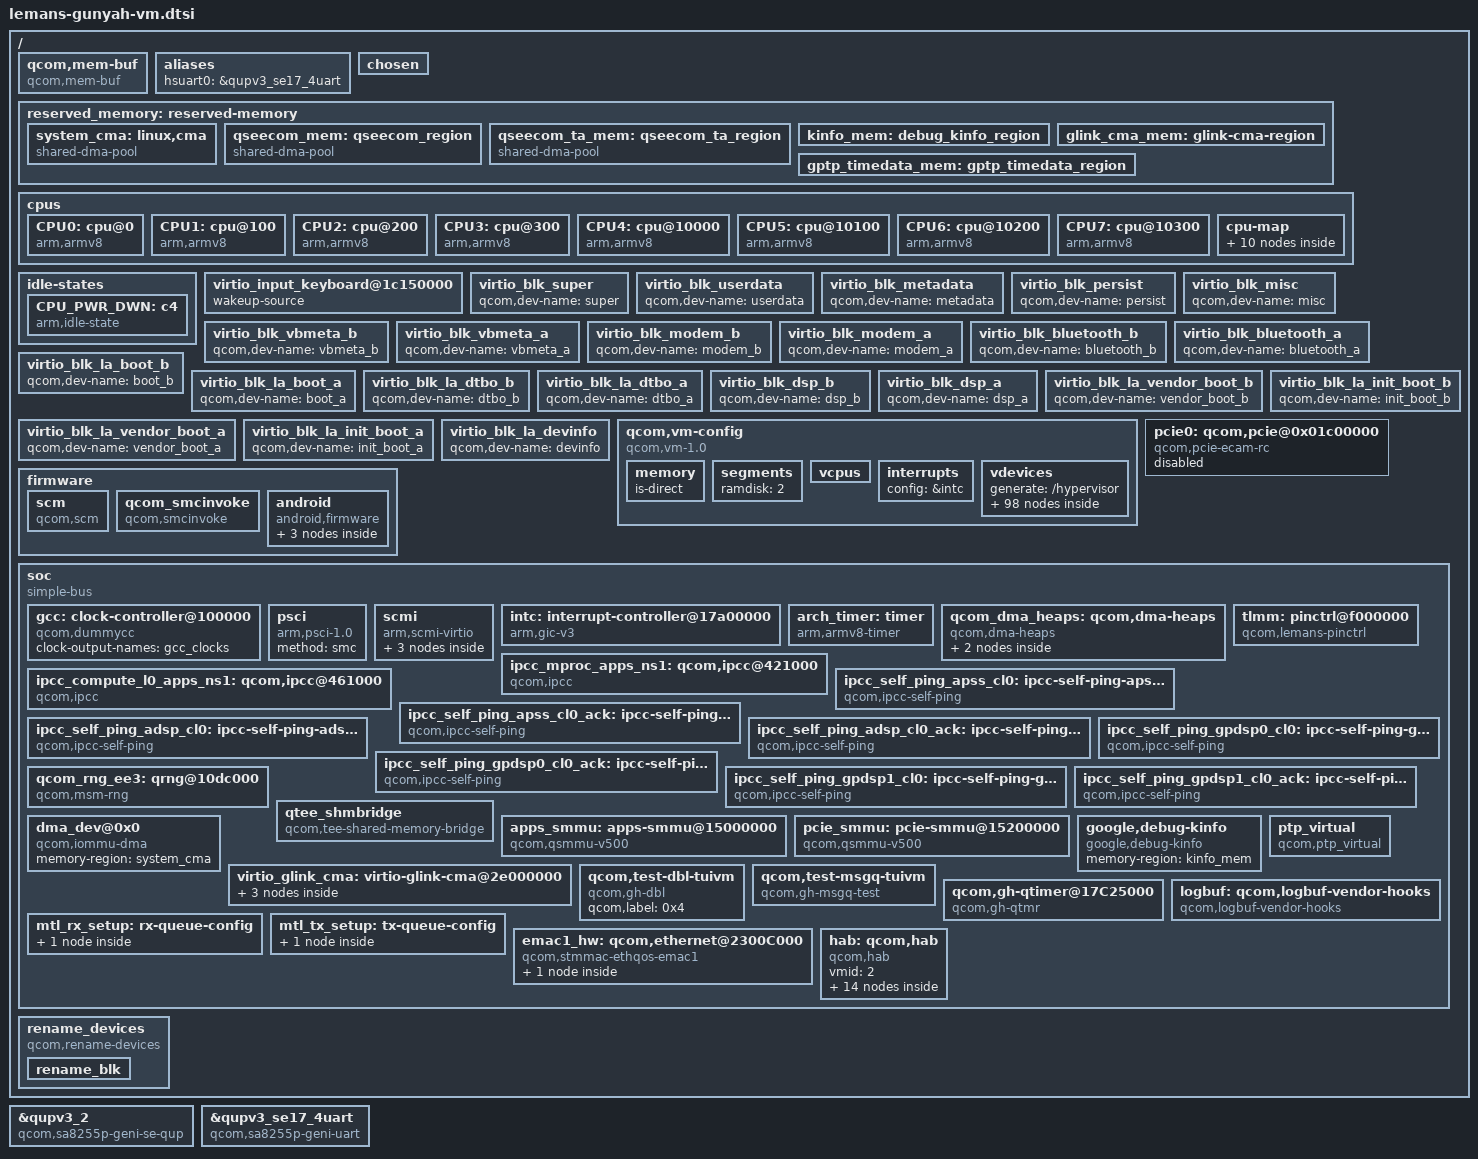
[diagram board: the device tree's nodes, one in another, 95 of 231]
#include <dt-bindings/interrupt-controller/arm-gic.h>
#include <dt-bindings/clock/qcom,gcc-lemans.h>
#include <dt-bindings/arm/msm/qcom_dma_heap_dt_constants.h>
#include <dt-bindings/mailbox/qcom-ipcc.h>
#include <dt-bindings/soc/qcom,ipcc.h>
/ {
	#address-cells = <0x2>;
	#size-cells = <0x2>;
	qcom,msm-id = <532 0x10000>, <533 0x10000>, <534 0x10000>, <532 0x20000>, <533 0x20000>, <534 0x20000>;
	interrupt-parent = <&intc>;

	qcom,mem-buf {
		compatible = "qcom,mem-buf";
		qcom,mem-buf-capabilities = "consumer";
		qcom,vmid = <52>;
	};

	aliases {
		hsuart0 = &qupv3_se17_4uart;
	};

	chosen {
		bootargs = "nokaslr log_buf_len=1M ufshcd-core.use_mcq_mode=n";
	};

	reserved_memory: reserved-memory {
		#address-cells = <2>;
		#size-cells = <2>;
		ranges;

		system_cma: linux,cma {
			compatible = "shared-dma-pool";
			alloc-ranges = <0x0 0x0 0x0 0xffffffff>;
			reusable;
			alignment = <0x0 0x400000>;
			size = <0x0 0x2000000>;
			linux,cma-default;
		};

		qseecom_mem: qseecom_region {
			compatible = "shared-dma-pool";
			alloc-ranges = <0x0 0x00000000 0x0 0xffffffff>;
			reusable;
			alignment = <0x0 0x400000>;
			size = <0x0 0x1400000>;
		};

		qseecom_ta_mem: qseecom_ta_region {
			compatible = "shared-dma-pool";
			alloc-ranges = <0x0 0x00000000 0x0 0xffffffff>;
			reusable;
			alignment = <0x0 0x400000>;
			size = <0x0 0x1000000>;
		};

		kinfo_mem: debug_kinfo_region {
			alloc-ranges = <0x0 0x0 0xffffffff 0xffffffff>;
			size = <0x0 0x1000>;
			no-map;
		};

		glink_cma_mem: glink-cma-region {
			no-map;
			qcom,label = <0x60>;
		};

		gptp_timedata_mem: gptp_timedata_region {
			no-map;
			qcom,label = <0x61>;
		};
	};

	cpus {
		#address-cells = <0x2>;
		#size-cells = <0x0>;

		CPU0: cpu@0 {
			compatible = "arm,armv8";
			reg = <0x0 0x0>;
			device_type = "cpu";
			enable-method = "psci";
			cpu-idle-states = <&CPU_PWR_DWN>;
		};

		CPU1: cpu@100 {
			compatible = "arm,armv8";
			reg = <0x0 0x100>;
			device_type = "cpu";
			enable-method = "psci";
			cpu-idle-states = <&CPU_PWR_DWN>;
		};

		CPU2: cpu@200 {
			compatible = "arm,armv8";
			reg = <0x0 0x200>;
			device_type = "cpu";
			enable-method = "psci";
			cpu-idle-states = <&CPU_PWR_DWN>;
		};

		CPU3: cpu@300 {
			compatible = "arm,armv8";
			reg = <0x0 0x300>;
			device_type = "cpu";
			enable-method = "psci";
			cpu-idle-states = <&CPU_PWR_DWN>;
		};

		CPU4: cpu@10000 {
			compatible = "arm,armv8";
			reg = <0x0 0x10000>;
			device_type = "cpu";
			enable-method = "psci";
			cpu-idle-states = <&CPU_PWR_DWN>;
		};

		CPU5: cpu@10100 {
			compatible = "arm,armv8";
			reg = <0x0 0x10100>;
			device_type = "cpu";
			enable-method = "psci";
			cpu-idle-states = <&CPU_PWR_DWN>;
		};

		CPU6: cpu@10200 {
			compatible = "arm,armv8";
			reg = <0x0 0x10200>;
			device_type = "cpu";
			enable-method = "psci";
			cpu-idle-states = <&CPU_PWR_DWN>;
		};

		CPU7: cpu@10300 {
			compatible = "arm,armv8";
			reg = <0x0 0x10300>;
			device_type = "cpu";
			enable-method = "psci";
			cpu-idle-states = <&CPU_PWR_DWN>;
		};

		cpu-map {
			cluster0 {
				core0 {
					cpu = <&CPU0>;
				};

				core1 {
					cpu = <&CPU1>;
				};

				core2 {
					cpu = <&CPU2>;
				};

				core3 {
					cpu = <&CPU3>;
				};
			};

			cluster1 {
				core0 {
					cpu = <&CPU4>;
				};

				core1 {
					cpu = <&CPU5>;
				};

				core2 {
					cpu = <&CPU6>;
				};

				core3 {
					cpu = <&CPU7>;
				};
			};
		};
	};

	idle-states {
		CPU_PWR_DWN: c4 { /* C4 */
			compatible = "arm,idle-state";
			idle-state-name = "rail-pc";
			entry-latency-us = <702>;
			exit-latency-us = <1061>;
			min-residency-us = <4488>;
			arm,psci-suspend-param = <0x40000004>;
			local-timer-stop;
		};
	};

	virtio_input_keyboard@1c150000 {
		wakeup-source;
	};

	virtio_blk_super {
		qcom,dev-name = "super";
	};

	virtio_blk_userdata {
		qcom,dev-name = "userdata";
	};

	virtio_blk_metadata {
		qcom,dev-name = "metadata";
	};

	virtio_blk_persist {
		qcom,dev-name = "persist";
	};

	virtio_blk_misc {
		qcom,dev-name = "misc";
	};

	virtio_blk_vbmeta_b {
		qcom,dev-name = "vbmeta_b";
	};

	virtio_blk_vbmeta_a {
		qcom,dev-name = "vbmeta_a";
	};

	virtio_blk_modem_b {
		qcom,dev-name = "modem_b";
	};

	virtio_blk_modem_a {
		qcom,dev-name = "modem_a";
	};

	virtio_blk_bluetooth_b {
		qcom,dev-name = "bluetooth_b";
	};

	virtio_blk_bluetooth_a {
		qcom,dev-name = "bluetooth_a";
	};

	virtio_blk_la_boot_b {
		qcom,dev-name = "boot_b";
	};

	virtio_blk_la_boot_a {
		qcom,dev-name = "boot_a";
	};

	virtio_blk_la_dtbo_b {
		qcom,dev-name = "dtbo_b";
	};

	virtio_blk_la_dtbo_a {
		qcom,dev-name = "dtbo_a";
	};

	virtio_blk_dsp_b {
		qcom,dev-name = "dsp_b";
	};

	virtio_blk_dsp_a {
		qcom,dev-name = "dsp_a";
	};

	virtio_blk_la_vendor_boot_b {
		qcom,dev-name = "vendor_boot_b";
	};

	virtio_blk_la_vendor_boot_a {
		qcom,dev-name = "vendor_boot_a";
	};

	virtio_blk_la_init_boot_b {
		qcom,dev-name = "init_boot_b";
	};

	virtio_blk_la_init_boot_a {
		qcom,dev-name = "init_boot_a";
	};

	virtio_blk_la_devinfo {
		qcom,dev-name = "devinfo";
	};

	qcom,vm-config {
		compatible = "qcom,vm-1.0";
		vm-type = "aarch64-guest";
		boot-config = "fdt,unified";
		os-type = "linux";
		kernel-entry-segment = "kernel";
		kernel-entry-offset = <0x0 0x0>;
		vendor = "QTI";
		image-name = "qcom,autoghgvm";
		qcom,pasid = <0x0 0x2c>;
		qcom,qtee-config-info = "p=3,16,57,77,78,7A,7C,8F,97,159,199,47E,7F1,10C;";
		qcom,secdomain-ids = <52 9 10>;
		qcom,primary-vm-index = <0>;
		vm-attrs = "guest-ram-dump", "vpm-virq";

		/* Pass through regions */
		iomemory-ranges = <
				/* TLMM region */
				0x0 0xF000000 0x0 0xF000000 0x0 0x1000000 0x0
				/* QUPv3 Tile 2 read-only region */
				0x0 0x8C0000 0x0 0x8C0000 0x0 0x1000 0x1
				0x0 0x8C1000 0x0 0x8C1000 0x0 0x1000 0x1
				/* QUPv3 SE17 region */
				0x0 0x88C000 0x0 0x88C000 0x0 0x1000 0x0
				0x0 0x88D000 0x0 0x88D000 0x0 0x1000 0x0
				0x0 0x88E000 0x0 0x88E000 0x0 0x1000 0x0
				/* QRNG region */
				0x0 0x10dc000 0x0 0x10dc000 0x0 0x1000 0x0
				/* MPROC NS1 IPCC region */
				0x0 0x421000 0x0 0x421000 0x0 0x1000 0x0
				/* Compute L0 IPCC region */
				0x0 0x461000 0x0 0x461000 0x0 0x1000 0x0
				0x0 0x1fd8000 0x0 0x1fd8000 0x0 0x1000 0x1
				0x0 0x1fd9000 0x0 0x1fd9000 0x0 0x1000 0x3
				0x0 0x1fdd000 0x0 0x1fdd000 0x0 0x1000 0x3
				0x0 0x1fdb000 0x0 0x1fdb000 0x0 0x1000 0x0
				0x0 0x1fdf000 0x0 0x1fdf000 0x0 0x1000 0x0
				/* Board serial number region */
				0x0 0x786000 0x0 0x786000 0x0 0x1000 0x1
				/* PTP region */
				0x0 0x23047000 0x0 0x23047000 0x0 0x1000 0x0
				/* Qtimer region */
				0x0 0x17c23000 0x0 0x17c23000 0x0 0x1000 0x0
				/* MPM timer read only*/
				0x0 0xc221000 0x0 0xc221000 0x0 0x1000 0x1
				/* PCIe0 region */
				0x4 0x0 0x4 0x0 0x0 0x10000000 0x0
				0x0 0x40000000 0x0 0x40000000 0x0 0x100000 0x0
				0x0 0x40100000 0x0 0x40100000 0x0 0x1ff00000 0x0
				0x4 0x10100000 0x4 0x10100000 0x0 0x100000 0x0
				/* EMAC1 CH4 region */
				0x0 0x2300C000 0x0 0x2300C000 0x0 0x1000 0x0
				>;

		/* Pass through IRQs */
		gic-irq-ranges = <
			/* QUPv3 SE17 GIC IRQ */
			617 617
			/* MPROC NS1 IPCC GIC IRQ */
			591 591
			/* Compute L0 IPCC GIC IRQ */
			588 588
			270 270
			271 271
			/* PCIe0 IRQs */
			339 339
			340 340
			341 341
			344 344
			345 345
			346 346
			406 406
			407 407
			/* EMAC1 CH4 GIC IRQ */
			808 808
			860 860
			>;

		memory {
			#address-cells = <0x2>;
			#size-cells = <0x0>;

			/* The IPA of the Guest regions is placed as IPA=PA */
			is-direct;
		};

		segments {
			ramdisk = <2>;
		};

		vcpus {
			config = "/cpus";
			affinity = "pinned";
			affinity-map = <0x7 0x6 0x5 0x4 0x3 0x2 0x1 0x0>;
			sched-priority = <0>;       /* relative to PVM */
			sched-timeslice = <5000>;   /* in ms */
		};

		interrupts {
			config = &intc;
		};

		vdevices {
			generate = "/hypervisor";
			minidump {
				vdevice-type = "minidump";
				push-compatible = "qcom,minidump_rm";
				minidump_allowed;
			};

			rm-rpc {
				vdevice-type = "rm-rpc";
				generate = "/hypervisor/qcom,resource-mgr";
				console-dev;
				message-size = <0x000000f0>;
				queue-depth = <0x00000008>;
				qcom,label = <0x1>;
			};

			virtio-mmio@0 {
				vdevice-type = "virtio-mmio";
				generate = "/virtio-mmio";
				peer-default;
				vqs-num = <0x1>;
				push-compatible = "virtio,mmio";
				sync-reset;
				dma-coherent;
				dma_base = <0x0 0x0>;
				memory {
					qcom,label = <0x20>;
					#address-cells = <0x2>;
					allocate-base;
				};
			};

			virtio-mmio@1 {
				vdevice-type = "virtio-mmio";
				patch = "/virtio_blk_la_devinfo";
				peer-default;
				vqs-num = <0x1>;
				push-compatible = "virtio,mmio";
				sync-reset;
				dma-coherent;
				dma_base = <0x0 0x4000>;
				memory {
					qcom,label = <0x21>;
					#address-cells = <0x2>;
					allocate-base;
				};
			};

			virtio-mmio@2 {
				vdevice-type = "virtio-mmio";
				patch = "/virtio_blk_la_init_boot_a";
				peer-default;
				vqs-num = <0x1>;
				push-compatible = "virtio,mmio";
				sync-reset;
				dma-coherent;
				dma_base = <0x0 0x8000>;
				memory {
					qcom,label = <0x22>;
					#address-cells = <0x2>;
					allocate-base;
				};
			};

			virtio-mmio@3 {
				vdevice-type = "virtio-mmio";
				patch = "/virtio_blk_la_init_boot_b";
				peer-default;
				vqs-num = <0x1>;
				push-compatible = "virtio,mmio";
				sync-reset;
				dma-coherent;
				dma_base = <0x0 0xC000>;
				memory {
					qcom,label = <0x23>;
					#address-cells = <0x2>;
					allocate-base;
				};
			};

			virtio-mmio@4 {
				vdevice-type = "virtio-mmio";
				patch = "/virtio_blk_la_vendor_boot_a";
				peer-default;
				vqs-num = <0x1>;
				push-compatible = "virtio,mmio";
				sync-reset;
				dma-coherent;
				dma_base = <0x0 0x10000>;
				memory {
					qcom,label = <0x24>;
					#address-cells = <0x2>;
					allocate-base;
				};
			};

			virtio-mmio@5 {
				vdevice-type = "virtio-mmio";
				patch = "/virtio_blk_la_vendor_boot_b";
				peer-default;
				vqs-num = <0x1>;
				push-compatible = "virtio,mmio";
				sync-reset;
				dma-coherent;
				dma_base = <0x0 0x14000>;
				memory {
					qcom,label = <0x25>;
					#address-cells = <0x2>;
					allocate-base;
				};
			};

			virtio-mmio@6 {
				vdevice-type = "virtio-mmio";
				patch = "/virtio_blk_dsp_a";
				peer-default;
				vqs-num = <0x1>;
				push-compatible = "virtio,mmio";
				sync-reset;
				dma-coherent;
				dma_base = <0x0 0x18000>;
				memory {
					qcom,label = <0x26>;
					#address-cells = <0x2>;
					allocate-base;
				};
			};

			virtio-mmio@7 {
				vdevice-type = "virtio-mmio";
				patch = "/virtio_blk_dsp_b";
				peer-default;
				vqs-num = <0x1>;
				push-compatible = "virtio,mmio";
				sync-reset;
				dma-coherent;
				dma_base = <0x0 0x1C000>;
				memory {
					qcom,label = <0x27>;
					#address-cells = <0x2>;
					allocate-base;
				};
			};

			virtio-mmio@8 {
				vdevice-type = "virtio-mmio";
				patch = "/virtio_blk_la_dtbo_a";
				peer-default;
				vqs-num = <0x1>;
				push-compatible = "virtio,mmio";
				sync-reset;
				dma-coherent;
				dma_base = <0x0 0x20000>;
				memory {
					qcom,label = <0x28>;
					#address-cells = <0x2>;
					allocate-base;
				};
			};

			virtio-mmio@9 {
				vdevice-type = "virtio-mmio";
				patch = "/virtio_blk_la_dtbo_b";
				peer-default;
				vqs-num = <0x1>;
				push-compatible = "virtio,mmio";
				sync-reset;
				dma-coherent;
				dma_base = <0x0 0x24000>;
				memory {
					qcom,label = <0x29>;
					#address-cells = <0x2>;
					allocate-base;
				};
			};

			virtio-mmio@10 {
				vdevice-type = "virtio-mmio";
				patch = "/virtio_blk_la_boot_a";
				peer-default;
				vqs-num = <0x1>;
				push-compatible = "virtio,mmio";
				sync-reset;
				dma-coherent;
				dma_base = <0x0 0x28000>;
				memory {
					qcom,label = <0x2A>;
					#address-cells = <0x2>;
					allocate-base;
				};
			};

			virtio-mmio@11 {
				vdevice-type = "virtio-mmio";
				patch = "/virtio_blk_la_boot_b";
				peer-default;
				vqs-num = <0x1>;
				push-compatible = "virtio,mmio";
				sync-reset;
				dma-coherent;
				dma_base = <0x0 0x2C000>;
				memory {
					qcom,label = <0x2B>;
					#address-cells = <0x2>;
					allocate-base;
				};
			};

			virtio-mmio@12 {
				vdevice-type = "virtio-mmio";
				patch = "/virtio_blk_bluetooth_a";
				peer-default;
				vqs-num = <0x1>;
				push-compatible = "virtio,mmio";
				sync-reset;
				dma-coherent;
				dma_base = <0x0 0x30000>;
				memory {
					qcom,label = <0x2C>;
					#address-cells = <0x2>;
					allocate-base;
				};
			};

			virtio-mmio@13 {
				vdevice-type = "virtio-mmio";
				patch = "/virtio_blk_bluetooth_b";
				peer-default;
				vqs-num = <0x1>;
				push-compatible = "virtio,mmio";
				sync-reset;
				dma-coherent;
				dma_base = <0x0 0x34000>;
				memory {
					qcom,label = <0x2D>;
					#address-cells = <0x2>;
					allocate-base;
				};
			};

			virtio-mmio@14 {
				vdevice-type = "virtio-mmio";
				patch = "/virtio_blk_modem_a";
				peer-default;
				vqs-num = <0x1>;
				push-compatible = "virtio,mmio";
				sync-reset;
				dma-coherent;
				dma_base = <0x0 0x38000>;
				memory {
					qcom,label = <0x2E>;
					#address-cells = <0x2>;
					allocate-base;
				};
			};

			virtio-mmio@15 {
				vdevice-type = "virtio-mmio";
				patch = "/virtio_blk_modem_b";
				peer-default;
				vqs-num = <0x1>;
				push-compatible = "virtio,mmio";
				sync-reset;
				dma-coherent;
				dma_base = <0x0 0x3C000>;
				memory {
					qcom,label = <0x2F>;
					#address-cells = <0x2>;
					allocate-base;
				};
			};

			virtio-mmio@16 {
				vdevice-type = "virtio-mmio";
				patch = "/virtio_blk_vbmeta_a";
				peer-default;
				vqs-num = <0x1>;
				push-compatible = "virtio,mmio";
				sync-reset;
				dma-coherent;
				dma_base = <0x0 0x40000>;
				memory {
					qcom,label = <0x30>;
					#address-cells = <0x2>;
					allocate-base;
				};
			};

			virtio-mmio@17 {
				vdevice-type = "virtio-mmio";
				patch = "/virtio_blk_vbmeta_b";
				peer-default;
				vqs-num = <0x1>;
				push-compatible = "virtio,mmio";
				sync-reset;
				dma-coherent;
				dma_base = <0x0 0x44000>;
				memory {
					qcom,label = <0x31>;
					#address-cells = <0x2>;
					allocate-base;
				};
			};

			virtio-mmio@18 {
				vdevice-type = "virtio-mmio";
				patch = "/virtio_blk_misc";
				peer-default;
				vqs-num = <0x1>;
				push-compatible = "virtio,mmio";
				sync-reset;
				dma-coherent;
				dma_base = <0x0 0x48000>;
				memory {
					qcom,label = <0x32>;
					#address-cells = <0x2>;
					allocate-base;
				};
			};

			virtio-mmio@19 {
				vdevice-type = "virtio-mmio";
				patch = "/virtio_blk_persist";
				peer-default;
				vqs-num = <0x1>;
				push-compatible = "virtio,mmio";
				sync-reset;
				dma-coherent;
				dma_base = <0x0 0x4C000>;
				memory {
					qcom,label = <0x33>;
					#address-cells = <0x2>;
					allocate-base;
				};
			};

			virtio-mmio@20 {
				vdevice-type = "virtio-mmio";
				patch = "/virtio_blk_metadata";
				peer-default;
				vqs-num = <0x1>;
				push-compatible = "virtio,mmio";
				sync-reset;
				dma-coherent;
				dma_base = <0x0 0x50000>;
				memory {
					qcom,label = <0x34>;
					#address-cells = <0x2>;
					allocate-base;
				};
			};

			virtio-mmio@21 {
				vdevice-type = "virtio-mmio";
				patch = "/virtio_blk_userdata";
				peer-default;
				vqs-num = <0x1>;
				push-compatible = "virtio,mmio";
				sync-reset;
				dma-coherent;
				dma_base = <0x0 0x54000>;
				memory {
					qcom,label = <0x35>;
					#address-cells = <0x2>;
					allocate-base;
				};
			};

			virtio-mmio@22 {
				vdevice-type = "virtio-mmio";
				patch = "/virtio_blk_super";
				peer-default;
				vqs-num = <0x1>;
				push-compatible = "virtio,mmio";
				sync-reset;
				dma-coherent;
				dma_base = <0x0 0x58000>;
				memory {
					qcom,label = <0x36>;
					#address-cells = <0x2>;
					allocate-base;
				};
			};

			virtio-mmio@23 {
				vdevice-type = "virtio-mmio";
				generate = "/virtio-mmio";
				peer-default;
				vqs-num = <0x2>;
				push-compatible = "virtio,mmio";
				sync-reset;
				dma-coherent;
				dma_base = <0x0 0x5C000>;
				memory {
					qcom,label = <0x37>;
					#address-cells = <0x2>;
					allocate-base;
				};
			};

			virtio-mmio@24 {
				vdevice-type = "virtio-mmio";
				generate = "/virtio-mmio";
				peer-default;
				vqs-num = <0x2>;
				push-compatible = "virtio,mmio";
				sync-reset;
				dma-coherent;
				dma_base = <0x0 0x64000>;
				memory {
					qcom,label = <0x38>;
					#address-cells = <0x2>;
					allocate-base;
				};
			};

			virtio-mmio@25 {
				vdevice-type = "virtio-mmio";
				generate = "/virtio-mmio";
				peer-default;
				vqs-num = <0x2>;
				push-compatible = "virtio,mmio";
				sync-reset;
				dma-coherent;
				dma_base = <0x0 0x6C000>;
				memory {
					qcom,label = <0x39>;
					#address-cells = <0x2>;
					allocate-base;
				};
			};

			virtio-mmio@26 {
				vdevice-type = "virtio-mmio";
				generate = "/virtio-mmio";
				peer-default;
				vqs-num = <0x2>;
				push-compatible = "virtio,mmio";
				sync-reset;
				dma-coherent;
				dma_base = <0x0 0x7C000>;
				memory {
					qcom,label = <0x3A>;
					#address-cells = <0x2>;
					allocate-base;
				};
			};

			virtio-mmio@27 {
				vdevice-type = "virtio-mmio";
				generate = "/virtio-mmio";
				peer-default;
				vqs-num = <0x8>;
				push-compatible = "virtio,mmio";
				sync-reset;
				dma-coherent;
				dma_base = <0x0 0x8C000>;
				memory {
					qcom,label = <0x3B>;
					#address-cells = <0x2>;
					allocate-base;
				};
			};

			virtio-mmio@28 {
				vdevice-type = "virtio-mmio";
				generate = "/virtio-mmio";
				peer-default;
				vqs-num = <0xA>;
				push-compatible = "virtio,mmio";
				sync-reset;
				dma-coherent;
				dma_base = <0x0 0xCC000>;
				memory {
					qcom,label = <0x3C>;
					#address-cells = <0x2>;
					allocate-base;
				};
			};

			virtio-mmio@29 {
				vdevice-type = "virtio-mmio";
				generate = "/virtio-mmio";
				peer-default;
				vqs-num = <0x6>;
				push-compatible = "virtio,mmio";
				sync-reset;
				dma-coherent;
				dma_base = <0x0 0x11C000>;
				memory {
					qcom,label = <0x3D>;
					#address-cells = <0x2>;
					allocate-base;
				};
			};

			virtio-mmio@30 {
				vdevice-type = "virtio-mmio";
				generate = "/virtio-mmio";
				peer-default;
				vqs-num = <0x6>;
				push-compatible = "virtio,mmio";
				sync-reset;
				dma-coherent;
				dma_base = <0x0 0x14C000>;
				memory {
					qcom,label = <0x3E>;
					#address-cells = <0x2>;
					allocate-base;
				};
			};

			virtio-mmio@31 {
				vdevice-type = "virtio-mmio";
				generate = "/virtio-mmio";
				virtio,device-type = <18>;
				peer-default;
				vqs-num = <0x2>;
				push-compatible = "virtio,mmio";
				sync-reset;
				dma-coherent;
				dma_base = <0x0 0x17C000>;
				memory {
					qcom,label = <0x3F>;
					#address-cells = <0x2>;
					allocate-base;
				};
			};

			virtio-mmio@32 {
				vdevice-type = "virtio-mmio";
				patch = "/virtio_input_keyboard@1c150000";
				virtio,device-type = <18>;
				peer-default;
				vqs-num = <0x2>;
				push-compatible = "virtio,mmio";
				sync-reset;
				dma-coherent;
				dma_base = <0x0 0x180000>;
				memory {
					qcom,label = <0x40>;
					#address-cells = <0x2>;
					allocate-base;
				};
			};

			virtio-mmio@33 {
				vdevice-type = "virtio-mmio";
				generate = "/virtio-mmio";
				peer-default;
				vqs-num = <0x2>;
				push-compatible = "virtio,mmio";
				sync-reset;
				dma-coherent;
				dma_base = <0x0 0x184000>;
				memory {
					qcom,label = <0x41>;
					#address-cells = <0x2>;
					allocate-base;
				};
			};

			virtio-mmio@34 {
				vdevice-type = "virtio-mmio";
				generate = "/virtio-mmio";
				peer-default;
				vqs-num = <0x2>;
				push-compatible = "virtio,mmio";
				sync-reset;
				dma-coherent;
				dma_base = <0x0 0x18C000>;
				memory {
					qcom,label = <0x42>;
					#address-cells = <0x2>;
					allocate-base;
				};
			};

			virtio-mmio@35 {
				vdevice-type = "virtio-mmio";
				generate = "/virtio-mmio";
				peer-default;
				vqs-num = <0x3>;
				push-compatible = "virtio,mmio";
				sync-reset;
				dma-coherent;
				dma_base = <0x0 0x194000>;
				memory {
					qcom,label = <0x43>;
					#address-cells = <0x2>;
					allocate-base;
				};
			};

			virtio-mmio@36 {
				vdevice-type = "virtio-mmio";
				patch = "/soc/virtio-glink-cma@2e000000";
				peer-default;
				vqs-num = <0x1>;
				push-compatible = "virtio,mmio";
				sync-reset;
				dma-coherent;
				dma_base = <0x0 0x1A0000>;
				memory {
					qcom,label = <0x44>;
					#address-cells = <0x2>;
					allocate-base;
				};
			};

			virtio-mmio@37 {
				vdevice-type = "virtio-mmio";
				generate = "/virtio-mmio";
				peer-default;
				vqs-num = <0x2>;
				push-compatible = "virtio,mmio";
				sync-reset;
				dma-coherent;
				dma_base = <0x0 0x1A2000>;
				memory {
					qcom,label = <0x45>;
					#address-cells = <0x2>;
					allocate-base;
				};
			};

			virtio-mmio@38 {
				vdevice-type = "virtio-mmio";
				generate = "/virtio-mmio";
				peer-default;
				vqs-num = <0x1>;
				push-compatible = "virtio,mmio";
				sync-reset;
				dma-coherent;
				dma_base = <0x0 0x1A6000>;
				memory {
					qcom,label = <0x46>;
					#address-cells = <0x2>;
					allocate-base;
				};
			};

			virtio-mmio@39 {
				vdevice-type = "virtio-mmio";
				generate = "/virtio-mmio";
				peer-default;
				vqs-num = <0x1>;
				push-compatible = "virtio,mmio";
				sync-reset;
				dma-coherent;
				dma_base = <0x0 0x1A8000>;
				memory {
					qcom,label = <0x47>;
					#address-cells = <0x2>;
					allocate-base;
				};
			};

			virtio-mmio@40 {
				vdevice-type = "virtio-mmio";
				generate = "/virtio-mmio";
				peer-default;
				vqs-num = <0x2>;
				push-compatible = "virtio,mmio";
				sync-reset;
				dma-coherent;
				dma_base = <0x0 0x1AA000>;
				memory {
					qcom,label = <0x48>;
					#address-cells = <0x2>;
					allocate-base;
				};
			};

			virtio-mmio@41 {
				vdevice-type = "virtio-mmio";
				generate = "/virtio-mmio";
				peer-default;
				vqs-num = <0x2>;
				push-compatible = "virtio,mmio";
				sync-reset;
				dma-coherent;
				dma_base = <0x0 0x1BA000>;
				memory {
					qcom,label = <0x49>;
					#address-cells = <0x2>;
					allocate-base;
				};
			};

			virtio-mmio@42 {
				vdevice-type = "virtio-mmio";
				generate = "/virtio-mmio";
				peer-default;
				vqs-num = <0x6>;
				push-compatible = "virtio,mmio";
				sync-reset;
				dma-coherent;
				dma_base = <0x0 0x1CA000>;
				memory {
					qcom,label = <0x4A>;
					#address-cells = <0x2>;
					allocate-base;
				};
			};

			virtio-mmio@43 {
				vdevice-type = "virtio-mmio";
				generate = "/virtio-mmio";
				peer-default;
				vqs-num = <0x2>;
				push-compatible = "virtio,mmio";
				sync-reset;
				dma-coherent;
				dma_base = <0x0 0x1FA000>;
				memory {
					qcom,label = <0x4B>;
					#address-cells = <0x2>;
					allocate-base;
				};
			};

			swiotlb-shm {
				vdevice-type = "shm";
				generate = "/swiotlb";
				push-compatible = "swiotlb";
				peer-default;
				dma_base = <0x0 0x1000000>;
				memory {
					qcom,label = <0x50>;
					#address-cells = <0x2>;
					allocate-base;
				};
			};

			vsmmu@15000000 {
				vdevice-type = "vsmmu-v2";
				smmu-handle = <0x15000000>;
				num-cbs = <0x4>;
				num-smrs = <0x4>;
				patch = "/soc/apps-smmu@15000000";
			};

			vsmmu@15200000 {
				vdevice-type = "vsmmu-v2";
				smmu-handle = <0x15200000>;
				num-cbs = <0x1>;
				num-smrs = <0x10>;
				patch = "/soc/pcie-smmu@15200000";
			};

			test-dbl-tuivm {
				vdevice-type = "doorbell";
				generate = "/hypervisor/test-dbl-tuivm";
				qcom,label = <0x4>;
				peer-default;
			};

			test-dbl-tuivm-source {
				vdevice-type = "doorbell-source";
				generate = "/hypervisor/test-dbl-tuivm-source";
				qcom,label = <0x4>;
				peer-default;
			};

			test-msgq-tuivm {
				vdevice-type = "message-queue-pair";
				generate = "/hypervisor/test-msgq-tuivm-pair";
				message-size = <0xf0>;
				queue-depth = <0x8>;
				qcom,label = <0x4>;
				peer-default;
			};

			vcpu-sched-test-msgq {
				vdevice-type = "message-queue-pair";
				generate = "/hypervisor/sched-test-msgq-pair";
				message-size = <0xf0>;
				queue-depth = <0x8>;
				qcom,label = <0x8>;
				peer-default;
			};
		};
	};

	firmware: firmware {
		scm {
			compatible = "qcom,scm";
		};

		qcom_smcinvoke {
			compatible = "qcom,smcinvoke";
		};

		android {
			compatible = "android,firmware";
			boot_devices = "70002000.virtio_blk_la_devinfo,70003000.virtio_blk_la_init_boot_a,70004000.virtio_blk_la_init_boot_b,70005000.virtio_blk_la_vendor_boot_a,70006000.virtio_blk_la_vendor_boot_b,70007000.virtio_blk_dsp_a,70008000.virtio_blk_dsp_b,70009000.virtio_blk_la_dtbo_a,7000a000.virtio_blk_la_dtbo_b,7000b000.virtio_blk_la_boot_a,7000c000.virtio_blk_la_boot_b,7000d000.virtio_blk_bluetooth_a,7000e000.virtio_blk_bluetooth_b,7000f000.virtio_blk_modem_a,70010000.virtio_blk_modem_b,70011000.virtio_blk_vbmeta_a,70012000.virtio_blk_vbmeta_b,70013000.virtio_blk_misc,70014000.virtio_blk_persist,70015000.virtio_blk_metadata,70016000.virtio_blk_userdata,70017000.virtio_blk_super";

			vbmeta {
				compatible = "android,vbmeta";
				parts = "vbmeta,system,vendor";
			};

			fstab {
				compatible = "android,fstab";
				vendor {
					compatible = "android,vendor";
					dev="/dev/block/platform/vdevs/1c0f0000.virtio_blk/vdc";
					type = "ext4";
					mnt_flags = "ro,barrier=1,discard";
					fsmgr_flags = "wait";
					status = "disabled";
				};
			};
		};
	};

	pcie0: qcom,pcie@0x01c00000 {
		compatible = "qcom,pcie-ecam-rc";
		reg = <0x4 0x00000000 0x0 0x10000000>;
		device_type = "pci";

		#address-cells = <3>;
		#size-cells = <2>;
		ranges = <0x01000000 0x0 0x40000000 0x0 0x40000000 0x0 0x100000>,
				<0x02000000 0x0 0x40100000 0x0 0x40100000 0x0 0x1ff00000>,
				<0x43000000 0x4 0x10100000 0x4 0x10100000 0x0 0x100000>;
		interrupt-parent = <&intc>;

		bus-range = <0x00 0xff>;
		dma-coherent;
		linux,pci-domain = <0>;

		power-domains = <&scmi_power 1>;
		power-domain-names = "power";

		interrupts = <GIC_SPI 307 IRQ_TYPE_LEVEL_HIGH>,
			<GIC_SPI 308 IRQ_TYPE_LEVEL_HIGH>,
			<GIC_SPI 309 IRQ_TYPE_LEVEL_HIGH>,
			<GIC_SPI 312 IRQ_TYPE_LEVEL_HIGH>,
			<GIC_SPI 313 IRQ_TYPE_LEVEL_HIGH>,
			<GIC_SPI 314 IRQ_TYPE_LEVEL_HIGH>,
			<GIC_SPI 374 IRQ_TYPE_LEVEL_HIGH>,
			<GIC_SPI 375 IRQ_TYPE_LEVEL_HIGH>;

		iommus = <&pcie_smmu 0x00 0x7f>;
		iommu-map = <0x0 &pcie_smmu 0x0000 0x1>,
			<0x100 &pcie_smmu 0x0001 0x1>;

		status = "disabled";
	};

	soc: soc { };
};

&soc {
	#address-cells = <1>;
	#size-cells = <1>;
	ranges = <0 0 0 0xffffffff>;
	compatible = "simple-bus";

	gcc: clock-controller@100000 {
		compatible = "qcom,dummycc";
		clock-output-names = "gcc_clocks";
		#clock-cells = <1>;
		#reset-cells = <1>;
	};

	psci {
		compatible = "arm,psci-1.0";
		method = "smc";
	};

	scmi {
		compatible = "arm,scmi-virtio";
		#address-cells = <1>;
		#size-cells = <0>;
		status = "ok";

		scmi_power: protocol@11 {
			reg = <0x11>;
			#power-domain-cells = <1>;
		};

		scmi_perf: protocol@13 {
			reg = <0x13>;
			#power-domain-cells = <1>;
		};

		scmi_reset: protocol@16 {
			reg = <0x16>;
			#reset-cells = <1>;
		};
	};

	intc: interrupt-controller@17a00000 {
		compatible = "arm,gic-v3";
		interrupt-controller;
		#interrupt-cells = <0x3>;
		#redistributor-regions = <1>;
		redistributor-stride = <0x0 0x20000>;
		reg = <0x17a00000 0x10000>,     /* GICD */
		      <0x17a60000 0x100000>;    /* GICR * 8 */
	};

	arch_timer: timer {
		compatible = "arm,armv8-timer";
		always-on;
		interrupts = <GIC_PPI 13 (GIC_CPU_MASK_SIMPLE(8) | IRQ_TYPE_LEVEL_LOW)>,
			     <GIC_PPI 14 (GIC_CPU_MASK_SIMPLE(8) | IRQ_TYPE_LEVEL_LOW)>,
			     <GIC_PPI 11 (GIC_CPU_MASK_SIMPLE(8) | IRQ_TYPE_LEVEL_LOW)>,
			     <GIC_PPI 12 (GIC_CPU_MASK_SIMPLE(8) | IRQ_TYPE_LEVEL_LOW)>;
		clock-frequency = <19200000>;
	};

	qcom_dma_heaps: qcom,dma-heaps {
		compatible = "qcom,dma-heaps";

		qcom,qseecom {
			qcom,dma-heap-name = "qcom,qseecom";
			qcom,dma-heap-type = <HEAP_TYPE_CMA>;
			memory-region = <&qseecom_mem>;
		};

		qcom,qseecom_ta {
			qcom,dma-heap-name = "qcom,qseecom-ta";
			qcom,dma-heap-type = <HEAP_TYPE_CMA>;
			memory-region = <&qseecom_ta_mem>;
		};
	};

	tlmm: pinctrl@f000000 {
		compatible = "qcom,lemans-pinctrl";
		reg = <0xf000000 0x1000000>;
		interrupts = <GIC_SPI 208 IRQ_TYPE_LEVEL_HIGH>;
		gpio-controller;
		#gpio-cells = <2>;
		interrupt-controller;
		#interrupt-cells = <2>;
	};

	ipcc_mproc_apps_ns1: qcom,ipcc@421000 {
		compatible = "qcom,ipcc";
		reg = <0x421000 0x1000>;
		interrupts = <GIC_SPI 559 IRQ_TYPE_LEVEL_HIGH>;
		interrupt-controller;
		#interrupt-cells = <3>;
		#mbox-cells = <2>;
		status = "ok";
	};

	ipcc_compute_l0_apps_ns1: qcom,ipcc@461000 {
		compatible = "qcom,ipcc";
		reg = <0x461000 0x1000>;
		interrupts = <GIC_SPI 556 IRQ_TYPE_LEVEL_HIGH>;
		interrupt-controller;
		#interrupt-cells = <3>;
		#mbox-cells = <2>;
		status = "ok";
	};

	ipcc_self_ping_apss_cl0: ipcc-self-ping-apss_cl0 {
		compatible = "qcom,ipcc-self-ping";
		mboxes = <&ipcc_compute_l0_apps_ns1 IPCC_CLIENT_APSS
				IPCC_COMPUTE_L0_SIGNAL_MSG>;
		interrupt-parent = <&ipcc_compute_l0_apps_ns1>;
		interrupts = <IPCC_CLIENT_APSS
				IPCC_COMPUTE_L0_SIGNAL_MSG
				IRQ_TYPE_EDGE_RISING>;
	};

	ipcc_self_ping_apss_cl0_ack: ipcc-self-ping-apss_cl0_ack {
		compatible = "qcom,ipcc-self-ping";
		mboxes = <&ipcc_compute_l0_apps_ns1 IPCC_CLIENT_APSS
				IPCC_COMPUTE_L0_SIGNAL_ACK>;
		interrupt-parent = <&ipcc_compute_l0_apps_ns1>;
		interrupts = <IPCC_CLIENT_APSS
				IPCC_COMPUTE_L0_SIGNAL_ACK
				IRQ_TYPE_EDGE_RISING>;
	};

	ipcc_self_ping_adsp_cl0: ipcc-self-ping-adsp_cl0 {
		compatible = "qcom,ipcc-self-ping";
		mboxes = <&ipcc_compute_l0_apps_ns1 IPCC_CLIENT_LPASS
				IPCC_COMPUTE_L0_SIGNAL_MSG>;
		interrupt-parent = <&ipcc_compute_l0_apps_ns1>;
		interrupts = <IPCC_CLIENT_LPASS
				IPCC_COMPUTE_L0_SIGNAL_MSG
				IRQ_TYPE_EDGE_RISING>;
	};

	ipcc_self_ping_adsp_cl0_ack: ipcc-self-ping-adsp_cl0_ack {
		compatible = "qcom,ipcc-self-ping";
		mboxes = <&ipcc_compute_l0_apps_ns1 IPCC_CLIENT_LPASS
				IPCC_COMPUTE_L0_SIGNAL_ACK>;
		interrupt-parent = <&ipcc_compute_l0_apps_ns1>;
		interrupts = <IPCC_CLIENT_LPASS
				IPCC_COMPUTE_L0_SIGNAL_ACK
				IRQ_TYPE_EDGE_RISING>;
	};

	ipcc_self_ping_gpdsp0_cl0: ipcc-self-ping-gpdsp0_cl0 {
		compatible = "qcom,ipcc-self-ping";
		mboxes = <&ipcc_compute_l0_apps_ns1 IPCC_CLIENT_GPDSP0
				IPCC_COMPUTE_L0_SIGNAL_MSG>;
		interrupt-parent = <&ipcc_compute_l0_apps_ns1>;
		interrupts = <IPCC_CLIENT_GPDSP0
				IPCC_COMPUTE_L0_SIGNAL_MSG
				IRQ_TYPE_EDGE_RISING>;
	};

	ipcc_self_ping_gpdsp0_cl0_ack: ipcc-self-ping-gpdsp0_cl0_ack {
		compatible = "qcom,ipcc-self-ping";
		mboxes = <&ipcc_compute_l0_apps_ns1 IPCC_CLIENT_GPDSP0
				IPCC_COMPUTE_L0_SIGNAL_ACK>;
		interrupt-parent = <&ipcc_compute_l0_apps_ns1>;
		interrupts = <IPCC_CLIENT_GPDSP0
				IPCC_COMPUTE_L0_SIGNAL_ACK
				IRQ_TYPE_EDGE_RISING>;
	};

	ipcc_self_ping_gpdsp1_cl0: ipcc-self-ping-gpdsp1_cl0 {
		compatible = "qcom,ipcc-self-ping";
		mboxes = <&ipcc_compute_l0_apps_ns1 IPCC_CLIENT_GPDSP1
				IPCC_COMPUTE_L0_SIGNAL_MSG>;
		interrupt-parent = <&ipcc_compute_l0_apps_ns1>;
		interrupts = <IPCC_CLIENT_GPDSP1
				IPCC_COMPUTE_L0_SIGNAL_MSG
				IRQ_TYPE_EDGE_RISING>;
	};

	ipcc_self_ping_gpdsp1_cl0_ack: ipcc-self-ping-gpdsp1_cl0_ack {
		compatible = "qcom,ipcc-self-ping";
		mboxes = <&ipcc_compute_l0_apps_ns1 IPCC_CLIENT_GPDSP1
				IPCC_COMPUTE_L0_SIGNAL_ACK>;
		interrupt-parent = <&ipcc_compute_l0_apps_ns1>;
		interrupts = <IPCC_CLIENT_GPDSP1
				IPCC_COMPUTE_L0_SIGNAL_ACK
				IRQ_TYPE_EDGE_RISING>;
	};

	qcom_rng_ee3: qrng@10dc000 {
		compatible = "qcom,msm-rng";
		reg = <0x10dc000 0x1000>;
		qcom,no-qrng-config;
		qcom,no-clock-support;
		status = "ok";
	};

	qtee_shmbridge {
		compatible = "qcom,tee-shared-memory-bridge";
		qcom,custom-bridge-size = <512>;
		qcom,support-hypervisor;
	};

	apps_smmu: apps-smmu@15000000 {
		/*
		 * reg, #global-interrupts & interrupts  properties will
		 * be added dynamically by bootloader.
		 */
		compatible = "qcom,qsmmu-v500", "qcom,virt-smmu";
		#iommu-cells = <2>;
		qcom,use-3-lvl-tables;
		dma-coherent;
	};

	pcie_smmu: pcie-smmu@15200000 {
		compatible = "qcom,qsmmu-v500","qcom,virt-smmu";
		#iommu-cells = <2>;
		qcom,use-3-lvl-tables;
		dma-coherent;
	};

	dma_dev@0x0 {
		compatible = "qcom,iommu-dma";
		memory-region = <&system_cma>;
	};

	google,debug-kinfo {
		compatible = "google,debug-kinfo";
		memory-region = <&kinfo_mem>;
	};

	virtio_glink_cma: virtio-glink-cma@2e000000 {
		glink_bridge: virtio-glink-bridge {
			compatible = "virtio,device49162";
			glink-edge {
				interrupt-parent = <&ipcc_mproc_apps_ns1>;
				interrupts = <IPCC_CLIENT_CDSP 0 IRQ_TYPE_EDGE_RISING>;
				mboxes = <&ipcc_mproc_apps_ns1 IPCC_CLIENT_CDSP 0>;
				label = "cdsp";
				qcom,glink-label = "cdsp";
			};

			glink-edge1 {
				interrupt-parent = <&ipcc_mproc_apps_ns1>;
				interrupts = <IPCC_CLIENT_NSP1 0 IRQ_TYPE_EDGE_RISING>;
				mboxes = <&ipcc_mproc_apps_ns1 IPCC_CLIENT_NSP1 0>;
				label = "cdsp1";
				qcom,glink-label = "cdsp1";
			};
		};
	};

	ptp_virtual {
		compatible = "qcom,ptp_virtual";
		reg = <0xacfff000 0x1000>,
			<0x23047000 0x1000>,
			<0x17c23000 0x1000>;
		reg-names = "ptp_carveout_mem",
				"ptp_reg",
				"qtimer_reg";
	};

	qcom,test-dbl-tuivm {
		compatible = "qcom,gh-dbl";
		qcom,label = <0x4>;
	};

	qcom,test-msgq-tuivm {
		compatible = "qcom,gh-msgq-test";
		gunyah-label = <4>;
		affinity = <0>;
	};

	qcom,gh-qtimer@17C25000 {
		compatible = "qcom,gh-qtmr";
		reg = <0x17425000 0x1000>;
		reg-names = "qtmr-base";
		interrupts = <GIC_SPI 10 IRQ_TYPE_LEVEL_HIGH>;
		interrupt-names = "qcom,qtmr-intr";
		qcom,secondary;
	};

	logbuf: qcom,logbuf-vendor-hooks {
		compatible = "qcom,logbuf-vendor-hooks";
	};

	mtl_rx_setup: rx-queue-config {
		snps,rx-queues-to-use = <1>;
		snps,rx-sched-sp;

		queue {
			snps,dcb-algorithm;
			snps,priority = <0x1>;
		};
	};

	mtl_tx_setup: tx-queue-config {
		snps,tx-queues-to-use = <1>;
		snps,tx-sched-sp;
		queue {
			snps,dcb-algorithm;
		};
	};

	emac1_hw: qcom,ethernet@2300C000 {
		compatible = "qcom,stmmac-ethqos-emac1";
		emac-core-version = <0x30010000>;
		qcom,arm-smmu;
		reg = <0x2300C000 0x1000>;
		reg-names = "stmmaceth";
		interrupts-extended = <&intc 0 776 4>, <&intc 0 828 4>;
		interrupt-names = "rx_ch0_intr", "tx_ch0_intr";
		snps,tso;
		snps,pbl = <32>;
		mac-address = [00 55 7B B5 7D f7];
		rx-fifo-depth = <4096>;
		tx-fifo-depth = <4096>;
		snps,mtl-rx-config = <&mtl_rx_setup>;
		snps,mtl-tx-config = <&mtl_tx_setup>;
		queue = <0>;
		emac1_emb_smmu: emac1_emb_smmu {
			compatible = "qcom,emac-thin-smmu-embedded";
			iommus = <&apps_smmu 0x148 0x1>;
			qcom,iommu-dma = "fastmap";
			qcom,iommu-dma-addr-pool = <0x80000000 0x40000000>;
		};
	};
};

/ {
	rename_devices: rename_devices {
		compatible = "qcom,rename-devices";
		rename_blk: rename_blk {
			device-type = "block";
			actual-dev =    "vda", "vdb", "vdc",
					"vdd", "vde", "vdf",
					"vdg", "vdh", "vdi",
					"vdj", "vdk", "vdl",
					"vdm", "vdn", "vdo",
					"vdp", "vdq", "vdr",
					"vds", "vdt", "vdu", "vdv";
			rename-dev = "super", "userdata", "metadata",
					"persist", "misc", "vbmeta_b",
					"vbmeta_a", "modem_b", "modem_a",
					"bluetooth_b", "bluetooth_a",
					"boot_b", "boot_a", "dtbo_b",
					"dtbo_a", "dsp_b", "dsp_a",
					"vendor_boot_b", "vendor_boot_a",
					"init_boot_b", "init_boot_a", "devinfo";
		};
	};
};

#include "lemans-pinctrl.dtsi"
#include "lemans-vm-qupv3.dtsi"

/delete-node/ &qupv3_1;

&qupv3_2 {
	/delete-property/ clocks;
	/delete-property/ clock-names;
	compatible = "qcom,sa8255p-geni-se-qup";
	reg = <0x8c0000 0x2000>;
	iommus = <&apps_smmu 0x5b8 0x0>;
	qcom,iommu-dma = "default";
	status = "ok";
};

&qupv3_se17_4uart {
	/delete-property/ clocks;
	/delete-property/ clock-names;
	/delete-property/ interconnects;
	/delete-property/ interconnect-names;
	/delete-property/ pinctrl-names;
	/delete-property/ pinctrl-0;
	/delete-property/ pinctrl-1;
	/delete-property/ pinctrl-2;
	/delete-property/ pinctrl-3;
	/delete-property/ interrupts-extended;
	/delete-property/ qcom,wakeup-byte;
	compatible = "qcom,sa8255p-geni-uart";
	reg = <0x88c000 0x3000>;
	interrupts = <GIC_SPI 585 IRQ_TYPE_LEVEL_HIGH>;

	power-domains = <&scmi_power 0>, <&scmi_perf 0>;
	power-domain-names = "power", "perf";
	status = "ok";
};

&soc {
	hab: qcom,hab {
		compatible = "qcom,hab";
		vmid = <2>;

		mmidgrp100: mmidgrp100 {
			grp-start-id = <100>;
			role = "fe";
			remote-vmids = <0>;
		};

		mmidgrp200: mmidgrp200 {
			grp-start-id = <200>;
			role = "fe";
			remote-vmids = <0>;
		};

		mmidgrp300: mmidgrp300 {
			grp-start-id = <300>;
			role = "fe";
			remote-vmids = <0>;
		};

		mmidgrp400: mmidgrp400 {
			grp-start-id = <400>;
			role = "fe";
			remote-vmids = <0>;
		};

		mmidgrp500: mmidgrp500 {
			grp-start-id = <500>;
			role = "fe";
			remote-vmids = <0>;
		};

		mmidgrp600: mmidgrp600 {
			grp-start-id = <600>;
			role = "fe";
			remote-vmids = <0>;
		};

		mmidgrp700: mmidgrp700 {
			grp-start-id = <700>;
			role = "fe";
			remote-vmids = <0>;
			kernel_only;
		};

		mmidgrp900: mmidgrp900 {
			grp-start-id = <900>;
			role = "fe";
			remote-vmids = <0>;
		};

		mmidgrp1000: mmidgrp1000 {
			grp-start-id = <1000>;
			role = "fe";
			remote-vmids = <0>;
		};

		mmidgrp1100: mmidgrp1100 {
			grp-start-id = <1100>;
			role = "fe";
			remote-vmids = <0>;
		};

		mmidgrp1200: mmidgrp1200 {
			grp-start-id = <1200>;
			role = "fe";
			remote-vmids = <0>;
		};

		mmidgrp1400: mmidgrp1400 {
			grp-start-id = <1400>;
			role = "fe";
			remote-vmids = <0>;
		};

		mmidgrp1500: mmidgrp1500 {
			grp-start-id = <1500>;
			role = "fe";
			remote-vmids = <0>;
		};

		mmidgrp1600: mmidgrp1600 {
			grp-start-id = <1600>;
			role = "fe";
			remote-vmids = <0>;
		};
	};
};
